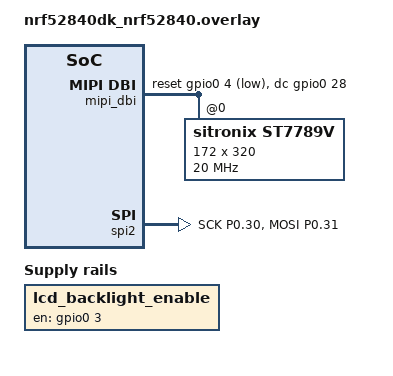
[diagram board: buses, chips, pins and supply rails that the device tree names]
/ {
    chosen {
        zephyr,display = &st7789v;
    };

    mipi_dbi {
        compatible = "zephyr,mipi-dbi-spi";
        spi-dev = <&spi2>;
        dc-gpios = <&gpio0 28 GPIO_ACTIVE_HIGH>;
        reset-gpios = <&gpio0 4 GPIO_ACTIVE_LOW>;
        write-only;
        #address-cells = <1>;
        #size-cells = <0>;
        status = "okay";

        st7789v: st7789v@0 {
            compatible = "sitronix,st7789v";
            reg = <0>;
            mipi-max-frequency = <20000000>;

            width = <172>;
            height = <320>;
            x-offset = <34>;
            y-offset = <0>;

            vcom = <0x19>;
            gctrl = <0x35>;
            vrhs = <0x12>;
            vdvs = <0x20>;
            mdac = <0x00>;
            gamma = <0x01>;
            colmod = <0x55>;
            lcm = <0x2c>;
            porch-param = [0c 0c 00 33 33];
            cmd2en-param = [5a 69 02 01];
            pwctrl1-param = [a4 a1];
            pvgam-param = [D0 04 0D 11 13 2B 3F 54 4C 18 0D 0B 1F 23];
            nvgam-param = [D0 04 0C 11 13 2C 3F 44 51 2F 1F 1F 20 23];
            ram-param = [00 F0];
            rgb-param = [CD 08 14];
            mipi-mode = "MIPI_DBI_MODE_SPI_4WIRE";
            status = "okay";
        };
    };

    lcd_backlight_en {
		compatible = "regulator-fixed";
		regulator-name = "lcd_backlight_enable";
		enable-gpios = <&gpio0 3 GPIO_ACTIVE_HIGH>;
		regulator-boot-on;
	};
};

&pinctrl {
    spi2_default: spi2_default {
        group1 {
            psels = <NRF_PSEL(SPIM_SCK, 0, 30)>,
                 <NRF_PSEL(SPIM_MOSI, 0, 31)>;
        };
    };

    spi2_sleep: spi2_sleep {
        group1 {
            psels = <NRF_PSEL(SPIM_SCK, 0, 30)>,
                 <NRF_PSEL(SPIM_MOSI, 0, 31)>;
            low-power-enable;
        };
    };
};

&spi2 {
    compatible = "nordic,nrf-spi";
    status = "okay";
    pinctrl-0 = <&spi2_default>;
    pinctrl-1 = <&spi2_sleep>;
    pinctrl-names = "default", "sleep";
    cs-gpios = <&gpio0 29 GPIO_ACTIVE_LOW>;
};

